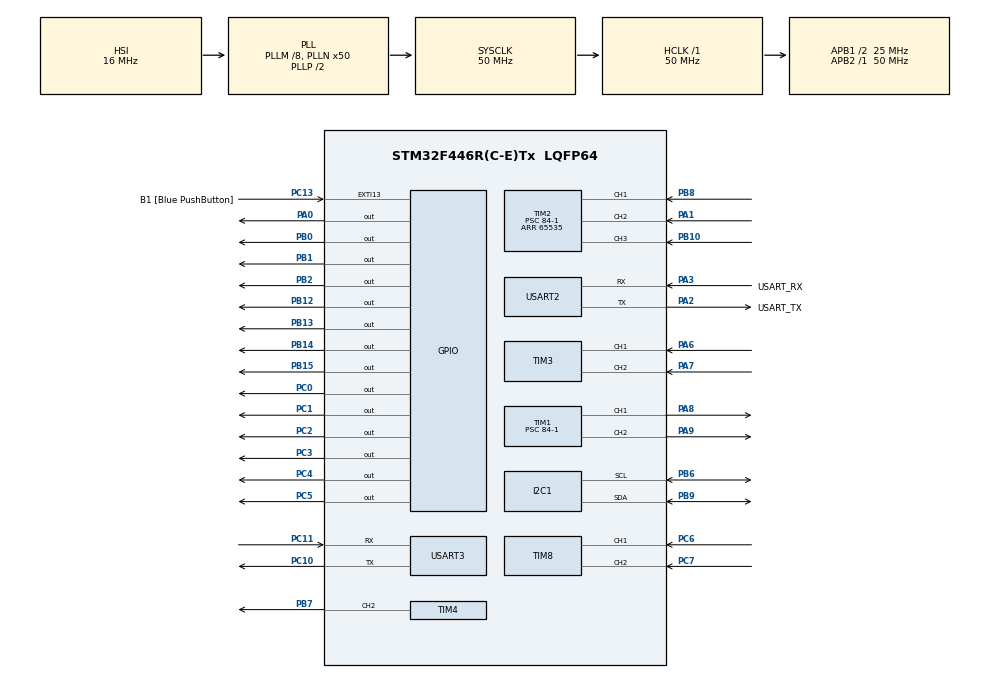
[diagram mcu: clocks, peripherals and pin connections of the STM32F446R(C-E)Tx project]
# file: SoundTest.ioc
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Dma.I2C1_RX.0.Direction=DMA_PERIPH_TO_MEMORY
Dma.I2C1_RX.0.FIFOMode=DMA_FIFOMODE_DISABLE
Dma.I2C1_RX.0.Instance=DMA1_Stream0
Dma.I2C1_RX.0.MemDataAlignment=DMA_MDATAALIGN_BYTE
Dma.I2C1_RX.0.MemInc=DMA_MINC_ENABLE
Dma.I2C1_RX.0.Mode=DMA_NORMAL
Dma.I2C1_RX.0.PeriphDataAlignment=DMA_PDATAALIGN_BYTE
Dma.I2C1_RX.0.PeriphInc=DMA_PINC_DISABLE
Dma.I2C1_RX.0.Priority=DMA_PRIORITY_HIGH
Dma.Request0=I2C1_RX
Mcu.Family=STM32F4
Mcu.Name=STM32F446R(C-E)Tx
Mcu.Package=LQFP64
NVIC.DMA1_Stream0_IRQn=true\:0\:0\:false\:false\:true\:false\:true\:true
NVIC.I2C1_ER_IRQn=true\:0\:0\:false\:false\:true\:true\:true\:true
NVIC.I2C1_EV_IRQn=true\:0\:0\:false\:false\:true\:true\:true\:true
NVIC.PriorityGroup=NVIC_PRIORITYGROUP_4
NVIC.TIM1_BRK_TIM9_IRQn=true\:0\:0\:false\:false\:true\:true\:true\:true
NVIC.TIM1_UP_TIM10_IRQn=true\:0\:0\:false\:false\:true\:true\:true\:true
NVIC.TIM2_IRQn=true\:0\:0\:false\:false\:true\:true\:true\:true
NVIC.TIM6_DAC_IRQn=true\:15\:0\:true\:false\:true\:true\:true\:true
NVIC.TIM7_IRQn=true\:0\:0\:false\:false\:true\:true\:true\:true
NVIC.USART2_IRQn=true\:0\:0\:false\:false\:true\:true\:true\:true
NVIC.USART3_IRQn=true\:0\:0\:false\:false\:true\:true\:true\:true
PA0-WKUP.Signal=GPIO_Output
PA1.Signal=S_TIM2_CH2
PA13.GPIO_Label=TMS
PA13.Mode=Serial_Wire
PA13.Signal=SYS_JTMS-SWDIO
PA14.GPIO_Label=TCK
PA14.Mode=Serial_Wire
PA14.Signal=SYS_JTCK-SWCLK
PA2.GPIO_Label=USART_TX
PA2.Mode=Asynchronous
PA2.Signal=USART2_TX
PA3.GPIO_Label=USART_RX
PA3.Mode=Asynchronous
PA3.Signal=USART2_RX
PA6.Signal=S_TIM3_CH1
PA7.Signal=S_TIM3_CH2
PA8.Signal=S_TIM1_CH1
PA9.Signal=S_TIM1_CH2
PB0.Signal=GPIO_Output
PB1.Signal=GPIO_Output
PB10.Signal=S_TIM2_CH3
PB12.Signal=GPIO_Output
PB13.Signal=GPIO_Output
PB14.Signal=GPIO_Output
PB15.Signal=GPIO_Output
PB2.Signal=GPIO_Output
PB3.GPIO_Label=SWO
PB3.Signal=SYS_JTDO-SWO
PB6.Mode=I2C
PB6.Signal=I2C1_SCL
PB7.Signal=S_TIM4_CH2
PB8.Signal=S_TIM2_CH1_ETR
PB9.Mode=I2C
PB9.Signal=I2C1_SDA
PC0.Signal=GPIO_Output
PC1.Signal=GPIO_Output
PC10.Mode=Asynchronous
PC10.Signal=USART3_TX
PC11.Mode=Asynchronous
PC11.Signal=USART3_RX
PC13.GPIO_Label=B1 [Blue PushButton]
PC13.GPIO_ModeDefaultEXTI=GPIO_MODE_IT_FALLING
PC13.Signal=GPXTI13
PC14-OSC32_IN.Mode=LSE-External-Oscillator
PC14-OSC32_IN.Signal=RCC_OSC32_IN
PC15-OSC32_OUT.Mode=LSE-External-Oscillator
PC15-OSC32_OUT.Signal=RCC_OSC32_OUT
PC2.Signal=GPIO_Output
PC3.Signal=GPIO_Output
PC4.Signal=GPIO_Output
PC5.Signal=GPIO_Output
PC6.Signal=S_TIM8_CH1
PC7.Signal=S_TIM8_CH2
PH0-OSC_IN.Mode=HSE-External-Oscillator
PH0-OSC_IN.Signal=RCC_OSC_IN
PH1-OSC_OUT.Mode=HSE-External-Oscillator
PH1-OSC_OUT.Signal=RCC_OSC_OUT
ProjectManager.HeapSize=0x200
ProjectManager.StackSize=0x400
ProjectManager.TargetToolchain=STM32CubeIDE
RCC.48MHZClocksFreq_Value=84000000
RCC.AHBFreq_Value=50000000
RCC.APB1CLKDivider=RCC_HCLK_DIV2
RCC.APB1Freq_Value=25000000
RCC.APB1TimFreq_Value=50000000
RCC.APB2Freq_Value=50000000
RCC.APB2TimFreq_Value=50000000
RCC.CortexFreq_Value=50000000
RCC.FLatency-AdvancedSettings=FLASH_LATENCY_1
RCC.HCLKFreq_Value=50000000
RCC.HSE_VALUE=8000000
RCC.HSI_VALUE=16000000
RCC.PLLM=8
RCC.PLLN=50
RCC.SYSCLKFreq_VALUE=50000000
RCC.SYSCLKSource=RCC_SYSCLKSOURCE_PLLCLK
RCC.USBFreq_Value=50000000
RCC.VCOOutputFreq_Value=100000000
SH.S_TIM1_CH1.0=TIM1_CH1,PWM Generation1 CH1
SH.S_TIM1_CH2.0=TIM1_CH2,PWM Generation2 CH2
SH.S_TIM2_CH1_ETR.0=TIM2_CH1,Input_Capture1_from_TI1
SH.S_TIM2_CH2.0=TIM2_CH2,Input_Capture2_from_TI2
SH.S_TIM2_CH3.0=TIM2_CH3,Input_Capture3_from_TI3
SH.S_TIM3_CH1.0=TIM3_CH1,Encoder_Interface
SH.S_TIM3_CH2.0=TIM3_CH2,Encoder_Interface
SH.S_TIM4_CH2.0=TIM4_CH2,PWM Generation2 CH2
SH.S_TIM8_CH1.0=TIM8_CH1,Encoder_Interface
SH.S_TIM8_CH2.0=TIM8_CH2,Encoder_Interface
TIM1.Channel-PWM\ Generation1\ CH1=TIM_CHANNEL_1
TIM1.Channel-PWM\ Generation2\ CH2=TIM_CHANNEL_2
TIM1.Period=999
TIM1.Prescaler=84-1
TIM2.Channel-Input_Capture1_from_TI1=TIM_CHANNEL_1
TIM2.Channel-Input_Capture2_from_TI2=TIM_CHANNEL_2
TIM2.Channel-Input_Capture3_from_TI3=TIM_CHANNEL_3
TIM2.Period=65535
TIM2.Prescaler=84-1
TIM4.Channel-PWM\ Generation2\ CH2=TIM_CHANNEL_2
TIM6.Period=99
TIM6.Prescaler=4999
TIM7.AutoReloadPreload=TIM_AUTORELOAD_PRELOAD_ENABLE
TIM7.Period=199
TIM7.Prescaler=4999
USART2.VirtualMode=VM_ASYNC
USART3.VirtualMode=VM_ASYNC
VP_TIM1_VS_ClockSourceINT.Mode=Internal
VP_TIM2_VS_ClockSourceINT.Mode=Internal
VP_TIM6_VS_ClockSourceINT.Mode=Enable_Timer
VP_TIM7_VS_ClockSourceINT.Mode=Enable_Timer
board=NUCLEO-F446RE

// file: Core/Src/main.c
/* USER CODE BEGIN Header */
/**
  ******************************************************************************
  * @file           : main.c
  * @brief          : Main program body
  ******************************************************************************
  * @attention
  *
  * Copyright (c) 2025 STMicroelectronics.
  * All rights reserved.
  *
  * This software is licensed under terms that can be found in the LICENSE file
  * in the root directory of this software component.
  * If no LICENSE file comes with this software, it is provided AS-IS.
  *
  ******************************************************************************
  */
/* USER CODE END Header */
#include "main.h"

/* USER CODE BEGIN Includes */
#include <stdio.h>    // printf, sprintf 사용
#include <stdarg.h>   // 가변 인자 사용
#include <math.h>
#include "ESP8266_HAL.h"
#include <string.h>   // strlen 사용
#include "stm32f4xx_hal.h" // HAL 함수 사용
#include "mpu6050.h"  // Edge-AI용 MPU6050 드라이버
#include "edge_ai_wrapper.h"  // Edge Impulse SDK Wrapper 헤더
#include "odom_imu.h"   //2D Mapping용 헤더파일

/* USER CODE END Includes */

/* USER CODE BEGIN PD */
// HC-SR04 핀 정의
#define TRIG_PIN    GPIO_PIN_0
#define TRIG_PORT    GPIOC
#define ECHO_PIN    GPIO_PIN_1
#define ECHO_PORT    GPIOA

#define TRIG_PIN1    GPIO_PIN_1
#define TRIG_PORT1    GPIOC
#define ECHO_PIN1    GPIO_PIN_8
#define ECHO_PORT1    GPIOB

#define TRIG_PIN2    GPIO_PIN_2
#define TRIG_PORT2    GPIOC
#define ECHO_PIN2    GPIO_PIN_10
#define ECHO_PORT2    GPIOB

uint8_t rx_data[100];

// 클럭 설정 (SystemClock_Config 기준 HCLK = 84MHz)
// 1초 = 84,000,000 사이클 -> 1us = 84 사이클
#define DWT_DELAY_UNIT (HAL_RCC_GetHCLKFreq() / 1000000)

// HC-SR04 관련 상수
#define SOUND_SPEED_CM_PER_US 0.0343 // 음속: 343m/s = 0.0343 cm/us
#define MAX_TIMEOUT_US 6000 // 30ms (HC-SR04 최대 측정 거리 고려)  //[최적화] 6000으로 변경

// 모터 1 (A) - ENA: TIM1_CH1 (PA8)
// 방향 핀
#define M1_IN1_PORT GPIOB
#define M1_IN1_PIN  GPIO_PIN_0
#define M1_IN2_PORT GPIOB
#define M1_IN2_PIN  GPIO_PIN_1

// 모터 2 (B) - ENB: TIM1_CH2 (PA9)
// 방향 핀
#define M2_IN1_PORT GPIOB
#define M2_IN1_PIN  GPIO_PIN_2
#define M2_IN2_PORT GPIOB
#define M2_IN2_PIN  GPIO_PIN_12

// 모터 3 (A) - ENA: TIM4_CH1 (Pb6)
#define M3_IN1_PORT GPIOC
#define M3_IN1_PIN  GPIO_PIN_3
#define M3_IN2_PORT GPIOC
#define M3_IN2_PIN  GPIO_PIN_4

// RGB LED 핀 정의
#define LED_R_PORT GPIOB
#define LED_R_PIN  GPIO_PIN_13
#define LED_G_PORT GPIOB
#define LED_G_PIN  GPIO_PIN_14
#define LED_B_PORT GPIOB
#define LED_B_PIN  GPIO_PIN_15

// RGB LED 색상 정의 (Common Cathode: Active High)
#define RGB_OFF         0, 0, 0
#define RGB_RED         1, 0, 0
#define RGB_GREEN       0, 1, 0
#define RGB_BLUE        0, 0, 1
#define RGB_YELLOW      1, 1, 0
#define RGB_MAGENTA     1, 0, 1
#define RGB_CYAN        0, 1, 1
#define RGB_WHITE       1, 1, 1

// LED 상태 타이밍 (ms)
#define LED_BLINK_INTERVAL_BASE    500   // 베이스 색상 표시 시간 (모드 색상)
#define LED_BLINK_INTERVAL_FLOOR   500   // 바닥 색상 표시 시간
#define LED_BLINK_INTERVAL_OBSTACLE 1000 // 장애물 회피 깜빡임

// LED 우선순위 상태 정의
typedef enum {
    LED_STATE_NORMAL = 0,        // 일반 동작 (모드/바닥 교차 깜빡임)
    LED_STATE_OBSTACLE = 1,      // 장애물 회피 (빨간색 깜빡임)
    LED_STATE_STANDBY = 2        // 대기 (빨간색 고정)
} LED_Priority_State_t;

// 모터 ID 및 방향 정의
#define MOTOR_A     1
#define MOTOR_B     2
#define MOTOR_C     3

#define FORWARD     1
#define BACKWARD    2
#define RIGHT    3 // 우회전
#define LEFT      4 // 좌회전 (필요시)
#define STOP        0

// PWM 최대값 (CubeMX TIM1 ARR 설정에 따라 변경될 수 있음. 여기서는 1000 가정)
#define PWM_MAX_VALUE 1000

// 벽 감지 임계 거리 (센티미터 단위)
#define WALL_DISTANCE_THRESHOLD 30.0f
// 직진 속도 및 회전 속도 (PWM 값)
#define BASE_SPEED          300
#define TURN_SPEED          300
// 회전 시간 상수 (90도 회전에 필요한 시간, 보정 필요)
#define TURN_90_TIME_MS     3200 // (모터와 바퀴에 따라 크게 달라짐)
// 유턴 시 전진/후진 거리 시간 (본체 폭만큼 이동하기 위한 시간, 보정 필요)
#define BODY_MOVE_TIME_MS   800 // 예시 값 (본체 폭에 따라 조절)

#define MPU6050_ADDR  (0x68 << 1)
#define PWR_MGMT_1    0x6B
#define ACCEL_XOUT_H  0x3B

// Edge-AI 관련 상수
#define EDGE_AI_SAMPLE_COUNT    200    // 2초 @ 100Hz (윈도우 크기)
#define EDGE_AI_AXES            3      // 3축 가속도
#define EDGE_AI_SLIDE_INTERVAL  100    // 1초마다 AI 판단 (100 샘플 = 1초)

/* USER CODE END PD */

I2C_HandleTypeDef hi2c1;
DMA_HandleTypeDef hdma_i2c1_rx;

TIM_HandleTypeDef htim1;
TIM_HandleTypeDef htim2;
TIM_HandleTypeDef htim3;
TIM_HandleTypeDef htim4;
TIM_HandleTypeDef htim6;
TIM_HandleTypeDef htim7;
TIM_HandleTypeDef htim8;

UART_HandleTypeDef huart2;
UART_HandleTypeDef huart3;

/* USER CODE BEGIN PV */
TIM_HandleTypeDef htim2;

//2D 맵핑용 위치변수
extern volatile float g_robot_x;
extern volatile float g_robot_y;
extern volatile float g_robot_yaw;

// Edge-AI 데이터 버퍼 (슬라이딩 윈도우 방식)
float edge_ai_buffer[EDGE_AI_SAMPLE_COUNT * EDGE_AI_AXES];
volatile uint16_t edge_ai_sample_index = 0;
volatile uint8_t edge_ai_buffer_ready = 0;
volatile uint16_t edge_ai_slide_counter = 0;  // 슬라이딩 인터벌 카운터

// IMU DMA 관련 변수 (비동기 I2C 통신용)
uint8_t imu_dma_buffer[6];           // DMA로 받은 6바이트 가속도 데이터
volatile uint8_t imu_dma_ready = 0;  // DMA 완료 플래그
volatile uint8_t imu_dma_busy = 0;   // DMA 전송 중 플래그

// IMU 센서 디버깅용 변수
volatile uint8_t imu_debug_counter = 0;  // 0.1초마다 출력하기 위한 카운터
volatile uint8_t imu_debug_ready = 0;    // 출력 준비 플래그
float imu_debug_ax, imu_debug_ay, imu_debug_az;  // 마지막 측정값 저장

// MQTT 관련 전역 변수
#define WIZFI360_MAX_RESPONSE_SIZE 512
char wizfi_rx_buffer[WIZFI360_MAX_RESPONSE_SIZE];

// MQTT Subscribe 수신 버퍼
#define MQTT_RX_BUF_SIZE 256
char mqtt_rx_buf[MQTT_RX_BUF_SIZE];
int mqtt_rx_len = 0;

// MQTT control 상태 변수
int g_powerOn = -1;          // 0 = OFF, 1 = ON
int g_fanSpeed = -1;         // 0~3
int g_modeManual = -1;       // 0 = AUTO, 1 = MANUAL
char g_direction[8] = "NULL";  // "FWD","BACK","LEFT","RIGHT","STOP"

// Edge-AI 판별 결과 저장 (실시간 업데이트)
char g_current_floor[16] = "Unknown";  // "Hard", "Carpet", "Dusty", "Unknown"

// LED 제어 상태 변수
LED_Priority_State_t g_led_priority_state = LED_STATE_NORMAL;
uint32_t g_led_last_update_tick = 0;
uint8_t g_led_toggle_state = 0;  // 0 or 1 (교차 깜빡임용)
/* USER CODE END PV */

void SystemClock_Config(void);
static void MX_GPIO_Init(void);
static void MX_DMA_Init(void);
static void MX_USART2_UART_Init(void);
static void MX_TIM2_Init(void);
static void MX_TIM1_Init(void);
static void MX_TIM4_Init(void);
static void MX_I2C1_Init(void);
static void MX_USART3_UART_Init(void);
static void MX_TIM3_Init(void);
static void MX_TIM8_Init(void);
static void MX_TIM6_Init(void);
static void MX_TIM7_Init(void);
/* USER CODE BEGIN PFP */
void DWT_Init(void);
void DWT_Delay_us(uint32_t us);
float HCSR04_Read(GPIO_TypeDef *trigPort, uint16_t trigPin,
                  GPIO_TypeDef *echoPort, uint16_t echoPin);
void UART_Printf(const char *format, ...);

// MQTT 함수 선언
void MQTT_ProcessResponseBuffer(uint8_t *buf, uint16_t len);

// RGB LED 제어 함수 선언
void set_rgb_led(uint8_t r, uint8_t g, uint8_t b);
void update_led_state(void);
void set_led_priority_state(LED_Priority_State_t state);

/* USER CODE END PFP */

/* USER CODE BEGIN 0 */

/**
  * @brief DWT (Data Watchpoint and Trace) 초기화 함수
  * @retval None
  */
void DWT_Init(void) {
    // TRCENA 활성화 (DWT 활성화)
    CoreDebug->DEMCR |= CoreDebug_DEMCR_TRCENA_Msk;
    // CYCCNT 카운터 초기화
    DWT->CYCCNT = 0;
    // CYCCNT 카운터 활성화
    DWT->CTRL |= DWT_CTRL_CYCCNTENA_Msk;
}

/**
  * @brief DWT 기반 마이크로초 지연 함수
  * @param us: 지연할 마이크로초
  * @retval None
  */
void DWT_Delay_us(uint32_t us) {
    uint32_t start_tick = DWT->CYCCNT;
    uint32_t delay_ticks = us * DWT_DELAY_UNIT;
    while ((DWT->CYCCNT - start_tick) < delay_ticks);
}

/**
  * @brief UART2를 이용한 printf 함수
  * @param format: 출력 형식 문자열
  * @retval None
  */
void UART_Printf(const char *format, ...) {
    char str[100];
    va_list args;
    va_start(args, format);
    vsprintf(str, format, args);
    va_end(args);
    // UART 전송 (Blocking 모드)
    HAL_UART_Transmit(&huart2, (uint8_t *)str, strlen(str), HAL_MAX_DELAY);
}

/**
  * @brief HC-SR04 거리 측정 함수
  * @retval 측정 거리 (cm), 실패 시 -1.0
  */
float HCSR04_Read(GPIO_TypeDef *trigPort, uint16_t trigPin,
                  GPIO_TypeDef *echoPort, uint16_t echoPin)
{
    uint32_t start_time, end_time, duration_cycles;

    HAL_GPIO_WritePin(trigPort, trigPin, GPIO_PIN_RESET);
    DWT_Delay_us(2);

    HAL_GPIO_WritePin(trigPort, trigPin, GPIO_PIN_SET);
    DWT_Delay_us(10);
    HAL_GPIO_WritePin(trigPort, trigPin, GPIO_PIN_RESET);

    start_time = DWT->CYCCNT;
    while (HAL_GPIO_ReadPin(echoPort, echoPin) == GPIO_PIN_RESET) {
        if ((DWT->CYCCNT - start_time) > (MAX_TIMEOUT_US * DWT_DELAY_UNIT))
            return -1.0f;
    }

    start_time = DWT->CYCCNT;
    while (HAL_GPIO_ReadPin(echoPort, echoPin) == GPIO_PIN_SET) {
        if ((DWT->CYCCNT - start_time) > (MAX_TIMEOUT_US * DWT_DELAY_UNIT))
            return -1.0f;
    }

    end_time = DWT->CYCCNT;
    duration_cycles = end_time - start_time;

    float distance = ((float)duration_cycles / (float)DWT_DELAY_UNIT)
                     * SOUND_SPEED_CM_PER_US / 2.0f;

    return distance;
}

/* 안전한 방향 제어 함수 */
void set_motor_direction(uint8_t motor_id, uint8_t direction)
{
    GPIO_TypeDef *in1_port = NULL, *in2_port = NULL;
    uint16_t in1_pin = 0, in2_pin = 0;

    if (motor_id == MOTOR_A) {
        in1_port = M1_IN1_PORT;
        in2_port = M1_IN2_PORT;
        in1_pin  = M1_IN1_PIN;
        in2_pin  = M1_IN2_PIN;
    } else if (motor_id == MOTOR_B) {
        in1_port = M2_IN1_PORT;
        in2_port = M2_IN2_PORT;
        in1_pin  = M2_IN1_PIN;
        in2_pin  = M2_IN2_PIN;
    }else if (motor_id == MOTOR_C) {
        in1_port = M3_IN1_PORT;
        in2_port = M3_IN2_PORT;
        in1_pin  = M3_IN1_PIN;
        in2_pin  = M3_IN2_PIN;
    }
    else {
        return;
    }

    if (direction == FORWARD) {
        HAL_GPIO_WritePin(in1_port, in1_pin, GPIO_PIN_SET);
        HAL_GPIO_WritePin(in2_port, in2_pin, GPIO_PIN_RESET);

    } else if (direction == BACKWARD) {
        HAL_GPIO_WritePin(in1_port, in1_pin, GPIO_PIN_RESET);
        HAL_GPIO_WritePin(in2_port, in2_pin, GPIO_PIN_SET);
    }
    else if (direction == BACKWARD) {
           HAL_GPIO_WritePin(in1_port, in1_pin, GPIO_PIN_RESET);
           HAL_GPIO_WritePin(in2_port, in2_pin, GPIO_PIN_SET);
       }
    else { // STOP (coast)
        HAL_GPIO_WritePin(in1_port, in1_pin, GPIO_PIN_RESET);
        HAL_GPIO_WritePin(in2_port, in2_pin, GPIO_PIN_RESET);
    }
}

/* 속도 설정은 그대로 사용하되 PWM_MAX와 TIM1 ARR 일치 확인 필요 */
void set_motor_speed(uint8_t motor_id, uint16_t speed)
{
    if (speed > PWM_MAX_VALUE) speed = PWM_MAX_VALUE;

    if (motor_id == MOTOR_A) {
        __HAL_TIM_SET_COMPARE(&htim1, TIM_CHANNEL_1, speed);
    } else if (motor_id == MOTOR_B) {
        __HAL_TIM_SET_COMPARE(&htim1, TIM_CHANNEL_2, speed);
    } else if (motor_id == MOTOR_C) {
        __HAL_TIM_SET_COMPARE(&htim4, TIM_CHANNEL_2, speed);
    }

}

/* --- 모터 제어 유틸 함수 추가 --- */
void stop_all_motors(void)
{
    set_motor_speed(MOTOR_A, 0);
    set_motor_speed(MOTOR_B, 0);
    set_motor_speed(MOTOR_C, 0);

    set_motor_direction(MOTOR_A, STOP);
    set_motor_direction(MOTOR_B, STOP);
    set_motor_direction(MOTOR_C, STOP);
}

void move_forward_pwm(uint16_t pwm)
{
    set_motor_direction(MOTOR_A, FORWARD);
    set_motor_direction(MOTOR_B, FORWARD);
    set_motor_speed(MOTOR_A, pwm);
    set_motor_speed(MOTOR_B, pwm);
}

void move_backward_pwm(uint16_t pwm)
{
    set_motor_direction(MOTOR_A, BACKWARD);
    set_motor_direction(MOTOR_B, BACKWARD);
    set_motor_speed(MOTOR_A, pwm);
    set_motor_speed(MOTOR_B, pwm);
}

void rotate_right_inplace(uint16_t pwm) // 오른쪽으로 제자리 회전 (좌/우 휠 반대방향)
{
    // 왼쪽 앞바퀴 전진, 오른쪽 바퀴 후진 -> 우회전
    set_motor_direction(MOTOR_A, FORWARD);   // 왼쪽
    set_motor_direction(MOTOR_B, BACKWARD);  // 오른쪽
    set_motor_speed(MOTOR_A, pwm);
    set_motor_speed(MOTOR_B, pwm);
}

void rotate_left_inplace(uint16_t pwm) // 왼쪽으로 제자리 회전
{
    set_motor_direction(MOTOR_A, BACKWARD);
    set_motor_direction(MOTOR_B, FORWARD);
    set_motor_speed(MOTOR_A, pwm);
    set_motor_speed(MOTOR_B, pwm);
}

/* 간단한 유턴: 제자리 180도 회전 (두번 90도) */
void perform_u_turn(void)
{
    // 180도: 두 번 90도 회전
    rotate_right_inplace(TURN_SPEED);
    HAL_Delay(TURN_90_TIME_MS);
    stop_all_motors();
    HAL_Delay(100);

    rotate_right_inplace(TURN_SPEED);
    HAL_Delay(TURN_90_TIME_MS);
    stop_all_motors();
    HAL_Delay(100);
}

/* 장애물 발견 시 회피 시퀀스:
   1) 정지
   2) 백업(짧게)
   3) 제자리 회전 90도 (우회전)
   4) 전진 (몸체 폭 만큼)
   5) 유턴(180)으로 라인 닫기(옵션)
*/
void R_avoidance_sequence(void)
{
    // LED 상태를 장애물 회피 모드로 설정 (빨간색 고정)
    set_led_priority_state(LED_STATE_OBSTACLE);

    // 1) 정지
    stop_all_motors();
    HAL_Delay(50);

    // 2) 백업
    move_backward_pwm(BASE_SPEED);
    HAL_Delay(300); // 300ms 뒤로 (조정 필요)
    stop_all_motors();
    HAL_Delay(50);

    // 3) 제자리 우회전 90도
    rotate_right_inplace(TURN_SPEED);
    HAL_Delay(TURN_90_TIME_MS);
    stop_all_motors();
    HAL_Delay(50);

    // 4) 전진으로 통과
    move_forward_pwm(BASE_SPEED);
    HAL_Delay(BODY_MOVE_TIME_MS);
    stop_all_motors();
    HAL_Delay(50);

    // 3) 제자리 우회전 90도
        rotate_right_inplace(TURN_SPEED);
        HAL_Delay(TURN_90_TIME_MS);
        stop_all_motors();
        HAL_Delay(50);

    // 회피 완료 후 일반 모드로 복귀
    set_led_priority_state(LED_STATE_NORMAL);
}

void L_avoidance_sequence(void)
{
    // LED 상태를 장애물 회피 모드로 설정 (빨간색 고정)
    set_led_priority_state(LED_STATE_OBSTACLE);

    // 1) 정지
    stop_all_motors();
    HAL_Delay(50);

    // 2) 백업
    move_backward_pwm(BASE_SPEED);
    HAL_Delay(300); // 300ms 뒤로 (조정 필요)
    stop_all_motors();
    HAL_Delay(50);

    // 3) 제자리 좌회전 90도
    rotate_left_inplace(TURN_SPEED);
    HAL_Delay(TURN_90_TIME_MS);
    stop_all_motors();
    HAL_Delay(50);

    // 4) 전진으로 통과
    move_forward_pwm(BASE_SPEED);
    HAL_Delay(BODY_MOVE_TIME_MS);
    stop_all_motors();
    HAL_Delay(50);

    // 3) 제자리 좌회전 90도
        rotate_left_inplace(TURN_SPEED);
        HAL_Delay(TURN_90_TIME_MS);
        stop_all_motors();
        HAL_Delay(50);

    // 회피 완료 후 일반 모드로 복귀
    set_led_priority_state(LED_STATE_NORMAL);
}

/**
  * @brief RGB LED 색상 설정 함수
  * @param r: Red 상태 (0=OFF, 1=ON)
  * @param g: Green 상태 (0=OFF, 1=ON)
  * @param b: Blue 상태 (0=OFF, 1=ON)
  * @retval None
  */
void set_rgb_led(uint8_t r, uint8_t g, uint8_t b)
{
    HAL_GPIO_WritePin(LED_R_PORT, LED_R_PIN, r ? GPIO_PIN_SET : GPIO_PIN_RESET);
    HAL_GPIO_WritePin(LED_G_PORT, LED_G_PIN, g ? GPIO_PIN_SET : GPIO_PIN_RESET);
    HAL_GPIO_WritePin(LED_B_PORT, LED_B_PIN, b ? GPIO_PIN_SET : GPIO_PIN_RESET);
}

/**
  * @brief LED 우선순위 상태 설정 함수
  * @param state: LED_STATE_NORMAL, LED_STATE_OBSTACLE, LED_STATE_STANDBY
  * @retval None
  */
void set_led_priority_state(LED_Priority_State_t state)
{
    g_led_priority_state = state;
    g_led_toggle_state = 0;  // 상태 변경 시 토글 상태 초기화
    g_led_last_update_tick = HAL_GetTick();  // 타이머 리셋
}

/**
  * @brief LED 상태 업데이트 함수 (메인 루프에서 주기적으로 호출)
  * @retval None
  * @note 우선순위: STANDBY(최고) > OBSTACLE > NORMAL
  * @note 일반 모드: 베이스 색상(1000ms) ↔ 바닥 색상(500ms) 2:1 비율
  */

void update_led_state(void)
{
    uint32_t current_tick = HAL_GetTick();
    uint32_t interval;

    // 우선순위 1: 대기 상태 (모터 정지) - 빨간색 고정
    if (g_led_priority_state == LED_STATE_STANDBY) {
        set_rgb_led(RGB_RED);
        return;
    }

    // 우선순위 2: 장애물 회피 - 빨간색 고정 (점멸 없음)
    if (g_led_priority_state == LED_STATE_OBSTACLE) {
        set_rgb_led(RGB_RED);  // 빨간색 계속 켜짐
        return;
    }

    // 우선순위 3: 일반 동작
    // Manual Mode: 파란색 고정 (점멸 없음)
    if (g_modeManual == 1) {
        set_rgb_led(RGB_BLUE);  // 수동 모드는 파란색 고정
        return;
    }

    // Auto Mode: 노면 감지에 따른 교차 깜빡임 (1:1 비율)
    // g_led_toggle_state: 0 = 하얀색(500ms), 1 = 바닥 색상(500ms)

    // 현재 표시할 색상 먼저 결정
    uint8_t base_r = 1, base_g = 1, base_b = 1;  // 하얀색

    // 바닥 색상 결정 (Edge-AI 판별 결과에 따라)
    uint8_t floor_r, floor_g, floor_b;
    if (strcmp(g_current_floor, "Hard") == 0) {
        // Hard Floor -> Green (초록색)
        floor_r = 0; floor_g = 1; floor_b = 0;
    } else if (strcmp(g_current_floor, "Carpet") == 0) {
        // Carpet -> Magenta (자홍색)
        floor_r = 1; floor_g = 0; floor_b = 1;
    } else if (strcmp(g_current_floor, "Dusty") == 0) {
        // Dusty -> Red (빨간색)
        floor_r = 1; floor_g = 0; floor_b = 0;
    } else {
        // Unknown -> Off (꺼짐)
        floor_r = 0; floor_g = 0; floor_b = 0;
    }

    // 현재 상태에 따른 interval 설정
    if (g_led_toggle_state == 0) {
        interval = LED_BLINK_INTERVAL_BASE;  // 하얀색 표시 시간 (500ms)
    } else {
        interval = LED_BLINK_INTERVAL_FLOOR; // 바닥 색상 표시 시간 (500ms)
    }

    if (current_tick - g_led_last_update_tick >= interval) {
        // 다음 색상으로 전환
        g_led_toggle_state = !g_led_toggle_state;
        g_led_last_update_tick = current_tick;
    }

    // 현재 토글 상태에 따라 LED 색상 표시
    // toggle_state = 0 → 하얀색 표시 (1000ms 유지)
    // toggle_state = 1 → 바닥 색상 표시 (500ms 유지)
    if (g_led_toggle_state == 0) {
        set_rgb_led(base_r, base_g, base_b);  // 하얀색
    } else {
        set_rgb_led(floor_r, floor_g, floor_b);  // 바닥색
    }
}

/**
  * @brief 모터 제어를 위해 필요한 초기 설정을 수행합니다.
  * @retval None
  */
void motor_control_init(void)
{
    // 1. PWM 출력 시작 (PA8: ENA, PA9: ENB)
    HAL_TIM_PWM_Start(&htim1, TIM_CHANNEL_1);
    HAL_TIM_PWM_Start(&htim1, TIM_CHANNEL_2);
    HAL_TIM_PWM_Start(&htim4, TIM_CHANNEL_2);

    // 2. 초기 모터 방향 설정 (정지)
    set_motor_direction(MOTOR_A, STOP);
    set_motor_direction(MOTOR_B, STOP);
    set_motor_direction(MOTOR_C, STOP);

    // 3. 초기 모터 속도 설정 (0)
    set_motor_speed(MOTOR_A, 0);
    set_motor_speed(MOTOR_B, 0);
    set_motor_speed(MOTOR_C, 0);

}

// 현재 control 상태를 PuTTY(USART2)에 출력하는 디버그용 함수
void Send_AT_Command(UART_HandleTypeDef *huart_wiz, UART_HandleTypeDef *huart_term, const char *command, uint8_t *response_buffer, uint16_t buffer_size, uint32_t timeout)
{
    // 1. 터미널(huart_term, PuTTY)로 전송할 명령 표시
    char tx_log[64];
    int len = snprintf(tx_log, sizeof(tx_log), "\r\n[CMD] Sending: %s\r\n", command);
    HAL_UART_Transmit(huart_term, (uint8_t *)tx_log, len, HAL_MAX_DELAY);

    // 2. WizFi360 (huart_wiz)에 명령 전송 (명령어 끝에 CR+LF(\r\n) 필수)
    char cmd_with_crlf[128];
    snprintf(cmd_with_crlf, sizeof(cmd_with_crlf), "%s\r\n", command);
    HAL_UART_Transmit(huart_wiz, (uint8_t *)cmd_with_crlf, strlen(cmd_with_crlf), 500);

    // 3. 응답 수신 준비
    memset(response_buffer, 0, buffer_size); // 버퍼 초기화
    uint16_t index = 0;
    uint32_t start_tick = HAL_GetTick();

    // 4. WizFi360으로부터 응답 수신 (간단한 타임아웃 폴링 방식)
    while ((HAL_GetTick() - start_tick) < timeout)
    {
        uint8_t rx_byte;
        // HAL_UART_Receive는 지정된 타임아웃 내에 1바이트를 수신합니다.
        if (HAL_UART_Receive(huart_wiz, &rx_byte, 1, 100) == HAL_OK)
        {
            if (index < buffer_size - 1)
            {
                response_buffer[index++] = rx_byte;
            }
            // 새로운 바이트를 수신할 때마다 타임아웃을 연장합니다.
            start_tick = HAL_GetTick();
        }
    }

    // 5. 수신된 응답을 터미널(huart_term, PuTTY)로 출력
    char *rx_header = "[RSP] Response Received:\r\n";
    HAL_UART_Transmit(huart_term, (uint8_t *)rx_header, strlen(rx_header), HAL_MAX_DELAY);

    MQTT_ProcessResponseBuffer(response_buffer, index);

    // 수신된 raw 데이터를 그대로 터미널로 출력
    HAL_UART_Transmit(huart_term, response_buffer, index, HAL_MAX_DELAY);

    char *rx_footer = "\r\n[END] ----------------------------------\r\n";
    HAL_UART_Transmit(huart_term, (uint8_t *)rx_footer, strlen(rx_footer), HAL_MAX_DELAY);
}

// 현재 control 상태를 PuTTY(USART2)에 출력하는 디버그용 함수
static void Debug_PrintControlState(const char *topic, const char *json)
{
    char buf[160];

    int len = snprintf(buf, sizeof(buf),
                       "\r\n[CONTROL] topic = %s\r\n"
                       "          json  = %s\r\n"
                       "          power = %d, speed = %d, mode = %d, dir = %s\r\n",
                       topic,
                       json,
                       g_powerOn,
                       g_fanSpeed,
                       g_modeManual,
                       g_direction);

    HAL_UART_Transmit(&huart2, (uint8_t *)buf, len, HAL_MAX_DELAY);
}

// -----------------------------------------------------
// MQTT 초기화용 공용 AT 명령 함수들
// -----------------------------------------------------

uint8_t MQTT_SetConfig(
    UART_HandleTypeDef *huart_wiz,
    UART_HandleTypeDef *huart_term,
    const char *user,
    const char *pass,
    const char *clientID,
    int aliveTime,
    uint8_t *resp, uint16_t resp_size
) {
    char cmd[256];
    snprintf(cmd, sizeof(cmd),
             "AT+MQTTSET=\"%s\",\"%s\",\"%s\",%d",
             user, pass, clientID, aliveTime);

    Send_AT_Command(huart_wiz, huart_term, cmd, resp, resp_size, 3000);
    return strstr((char*)resp, "OK") != NULL;
}

uint8_t MQTT_SetTopics(
    UART_HandleTypeDef *huart_wiz,
    UART_HandleTypeDef *huart_term,
    const char *pubTopic,
    const char *subTopic,
    uint8_t *resp, uint16_t resp_size
) {
    char cmd[256];
    snprintf(cmd, sizeof(cmd),
             "AT+MQTTTOPIC=\"%s\",\"%s\"",
             pubTopic, subTopic);

    Send_AT_Command(huart_wiz, huart_term, cmd, resp, resp_size, 3000);
    return strstr((char*)resp, "OK") != NULL;
}

uint8_t MQTT_SetQos(
    UART_HandleTypeDef *huart_wiz,
    UART_HandleTypeDef *huart_term,
    int qos,
    uint8_t *resp, uint16_t resp_size
) {
    char cmd[32];
    snprintf(cmd, sizeof(cmd), "AT+MQTTQOS=%d", qos);

    Send_AT_Command(huart_wiz, huart_term, cmd, resp, resp_size, 2000);
    return strstr((char*)resp, "OK") != NULL;
}

uint8_t MQTT_ConnectBroker(
    UART_HandleTypeDef *huart_wiz,
    UART_HandleTypeDef *huart_term,
    const char *brokerIP,
    int port,
    uint8_t *resp, uint16_t resp_size
) {
    char cmd[128];
    snprintf(cmd, sizeof(cmd),
             "AT+MQTTCON=0,\"%s\",%d",
             brokerIP, port);

    Send_AT_Command(huart_wiz, huart_term, cmd, resp, resp_size, 6000);

    return strstr((char*)resp, "CONNECT") || strstr((char*)resp, "OK");
}

uint8_t MQTT_Init_All(
    UART_HandleTypeDef *huart_wiz,
    UART_HandleTypeDef *huart_term
){
    uint8_t resp[512];

    // -------- Wi-Fi 연결 --------
    Send_AT_Command(huart_wiz, huart_term, "AT", resp, sizeof(resp), 1000);
    Send_AT_Command(huart_wiz, huart_term, "AT+RST", resp, sizeof(resp), 5000);
    Send_AT_Command(huart_wiz, huart_term, "AT+CWMODE=1", resp, sizeof(resp), 2000);

    // WiFi 접속
    Send_AT_Command(huart_wiz, huart_term,
        "AT+CWJAP=\"S24\",\"dial8787@@\"",
        resp, sizeof(resp), 5000);

    // -------- MQTT 설정 --------
    if (!MQTT_SetConfig(huart_wiz, huart_term,
                        "", "", "STM32_AI", 300,
                        resp, sizeof(resp))) return 0;

    if (!MQTT_SetTopics(huart_wiz, huart_term,
                        "vibeclean/robot1/ai2D",
                        "vibeclean/robot1/control/#",
                        resp, sizeof(resp))) return 0;

    if (!MQTT_SetQos(huart_wiz, huart_term, 0, resp, sizeof(resp)))
        return 0;

    if (!MQTT_ConnectBroker(huart_wiz, huart_term,
                            "10.96.250.61", 1883,
                            resp, sizeof(resp)))
        return 0;

    return 1;
}

void Publish_Message(void)
{
    char cmd[512];
    char json_message[400];

    // 실시간 센서 데이터와 AI 판별 결과를 포함한 JSON 생성
    snprintf(json_message, sizeof(json_message),
    		"{"
    		        "\"currentFloor\":\"%s\","
    		        "\"fanSpeed\":%d,"
    		        "\"position\":{"
    		            "\"x\":%.2f,"
    		            "\"y\":%.2f"
    		        "},"
    		        "\"sensor\":{"
    		            "\"x\":%.3f,"
    		            "\"y\":%.3f,"
    		            "\"z\":%.3f"
    		        "}"
    		    "}",
    		    g_current_floor,
    		    0,
    		    g_robot_x,
    		    g_robot_y,
    		    imu_debug_ax,
    		    imu_debug_ay,
    		    imu_debug_az
    		);

    // topic은 이미 AT+MQTTTOPIC로 설정되어 있으므로 메시지만 전달
    snprintf(cmd, sizeof(cmd), "AT+MQTTPUB=\"%s\"", json_message);
    Send_AT_Command(&huart3, &huart2, cmd, wizfi_rx_buffer, WIZFI360_MAX_RESPONSE_SIZE, 1000);
//    WizFi_SendOnly(&huart3, &huart2, cmd); //wizfi통해서 보내기만 하는 애
}

// 토픽과 JSON을 보고 상태 변수에 반영
void HandleControlJson(const char *topic, const char *json)
{
    if (strstr(topic, "control/power")) {
        if (strstr(json, "\"ON\""))  g_powerOn = 1;
        if (strstr(json, "\"OFF\"")) g_powerOn = 0;
    }
    else if (strstr(topic, "control/speed")) {
        int v = 0;
        // 숫자 하나만 뽑는 단순 파서 (예: {"fanSpeed":2})
        sscanf(json, "%*[^0-9]%d", &v);
        if (v < 0) v = 0;
        if (v > 3) v = 3;
        g_fanSpeed = v;
    }
    else if (strstr(topic, "control/mode")) {
        if (strstr(json, "\"MANUAL\"")) g_modeManual = 1;
        if (strstr(json, "\"AUTO\""))   g_modeManual = 0;
    }
    else if (strstr(topic, "control/direction")) {
        if (strstr(json, "\"FWD\""))   strcpy(g_direction, "FWD");
        else if (strstr(json, "\"BACK\""))  strcpy(g_direction, "BACK");
        else if (strstr(json, "\"LEFT\""))  strcpy(g_direction, "LEFT");
        else if (strstr(json, "\"RIGHT\"")) strcpy(g_direction, "RIGHT");
        else if (strstr(json, "\"STOP\""))  strcpy(g_direction, "STOP");
    }

    Debug_PrintControlState(topic, json);
}

// WizFi360이 보낸 한 줄(line)을 토픽 / json 으로 분리
void ParseMqttLine(char *line, int len)
{
    line[len] = '\0';

    // "topic->\"...\"" 형식에서 화살표 위치 찾기
    char *arrow = strstr(line, "->");
    if (!arrow) return;

    *arrow = '\0';
    char *topic = line;
    char *payload = arrow + 2;

    // 공백/따옴표 건너뛰기
    while (*payload == ' ' || *payload == '"' || *payload == '\r' || *payload == '\n')
        payload++;

    // JSON 시작 '{' 위치 찾기
    char *brace = strchr(payload, '{');
    if (!brace) return;

    char *end = strrchr(brace, '}');
    if (!end) return;
    *(end + 1) = '\0';   // JSON 문자열을 '\0'로 끝나게

    HandleControlJson(topic, brace);
}

// WizFi360 응답 버퍼 전체에서 "topic -> { json }" 형태의 구독 메시지를 찾아 처리
void MQTT_ProcessResponseBuffer(uint8_t *buf, uint16_t len)
{
    char line[256];
    uint16_t pos = 0;

    for (uint16_t i = 0; i < len; i++) {
        char c = (char)buf[i];

        // CR은 무시
        if (c == '\r') {
            continue;
        }

        // 줄 끝이거나 line 버퍼가 꽉 찬 경우
        if (c == '\n' || pos >= sizeof(line) - 1) {

            if (pos > 0) {
                line[pos] = '\0';

                // "->" 들어간 라인만 MQTT 메시지로 인정
                if (strstr(line, "->")) {
                    ParseMqttLine(line, strlen(line));
                }
            }

            pos = 0;
        }
        else {
            // 일반 문자는 line에 저장
            line[pos++] = c;
        }
    }

    // 마지막 라인이 '\n' 없이 종료되었을 때 처리
    if (pos > 0) {
        line[pos] = '\0';
        if (strstr(line, "->")) {
            ParseMqttLine(line, strlen(line));
        }
    }
}
/* USER CODE END 0 */

int main(void)
{

  /* USER CODE BEGIN 1 */
//Putty 작동 테스트용 변수
	int countL, countR; //  엔코더 카운트 저장 변수
	char debug_msg[100]; // 디버깅 메시지 버퍼

  /* USER CODE END 1 */

  /* MCU Configuration--------------------------------------------------------*/

  /* Reset of all peripherals, Initializes the Flash interface and the Systick. */
  HAL_Init();

  /* Configure the system clock */
  SystemClock_Config();

  /* Initialize all configured peripherals */
  MX_GPIO_Init();
  MX_DMA_Init();
  MX_USART2_UART_Init();
  MX_TIM2_Init();
  MX_TIM1_Init();
  MX_TIM4_Init();
  MX_I2C1_Init();
  MX_USART3_UART_Init();
  MX_TIM3_Init();
  MX_TIM8_Init();
  MX_TIM6_Init();
  MX_TIM7_Init();
  /* USER CODE BEGIN 2 */
  // [추가] TIM7 인터럽트 시작 (50Hz = 20ms 주기)
     if (HAL_TIM_Base_Start_IT(&htim7) != HAL_OK) {
         Error_Handler();
     }
     Odom_IMU_Init(&hi2c1, &htim3, &htim8);
     UART_Printf("Odom & IMU System Initialized (Gyro Calibrated)\r\n");

     UART_Printf("TIM7 Odometry Timer Started (50Hz)\r\n");
  // DWT 초기화 (마이크로초 측정을 위해 필수)
  DWT_Init();
  UART_Printf("STM32 HC-SR04 Measurement Ready (Trig: PA0, Echo: PA1)\r\n");

  motor_control_init(); // <- 반드시 호출 (PWM Start + 초기화)
  HAL_TIM_PWM_Start(&htim4, TIM_CHANNEL_1);

  //엔코더 카운팅 시작
  HAL_TIM_Encoder_Start(&htim3, TIM_CHANNEL_ALL);
  HAL_TIM_Encoder_Start(&htim8, TIM_CHANNEL_ALL);

  // Edge-AI 초기화
  UART_Printf("\r\n=== VibeClean ===\r\n");

  // I2C 통신 테스트
  UART_Printf("Testing I2C communication...\r\n");
  uint8_t who_am_i = MPU6050_WhoAmI(&hi2c1);
  UART_Printf("WHO_AM_I Register: 0x%02X (Expected: 0x68)\r\n", who_am_i);

  // MPU6050 센서 초기화
  UART_Printf("Initializing MPU6050...\r\n");
  HAL_StatusTypeDef mpu_status = MPU6050_Init(&hi2c1);

  if (mpu_status == HAL_OK) {
      UART_Printf("MPU6050 Init: OK\r\n");
  } else {
      UART_Printf("MPU6050 Init: FAILED! (Status: %d)\r\n", mpu_status);
      UART_Printf("Check I2C connections (SDA: PB9, SCL: PB8)\r\n");
      UART_Printf("Check MPU6050 power supply (3.3V)\r\n");
      UART_Printf("Check pull-up resistors on SDA/SCL (4.7k ohm)\r\n");
  }

  // Edge Impulse 분류기 초기화
  if (edge_ai_init() == 0) {
      UART_Printf("Edge Impulse Init: OK\r\n");
  } else {
      UART_Printf("Edge Impulse Init: FAILED!\r\n");
  }

  // TIM6 100Hz 인터럽트 시작
  HAL_TIM_Base_Start_IT(&htim6);
  UART_Printf("TIM6 100Hz Timer: Started\r\n");
  UART_Printf("Collecting %d samples (%.1f seconds)...\r\n\r\n",
              EDGE_AI_SAMPLE_COUNT, EDGE_AI_SAMPLE_COUNT / 100.0f);

  // RGB LED 초기화 (초기 상태: OFF)
  set_rgb_led(RGB_OFF);
  UART_Printf("RGB LED: Initialized\r\n");

  /* USER CODE END 2 */

  /* Infinite loop */
  /* USER CODE BEGIN WHILE */
  int failCount = 0;
  int tempAovoid = 0; // 0 = right, 1 = left

  char post_data_buffer[150]; //json 문자열 버퍼
  uint32_t last_pub_tick = 0; // 마지막 메시지 발행 시간 저장

  char *start_msg = "STM32 WizFi360 MQTT Test Start! (PuTTY=USART2, WizFi360=USART3)\r\n";
  //  HAL_UART_Transmit(&huart2, (uint8_t *)start_msg, strlen(start_msg), HAL_MAX_DELAY);

  HAL_Delay(3000); // WizFi360 부팅 대기

  //  Setup_WiFi_And_MQTT();
  MQTT_Init_All(&huart3, &huart2);   // Wiz: huart1, Terminal: huart2

  while (1)
  {
	  // ==========================================================
	  // [1] MQTT Publish & Data Receiving (데이터 수신/발신 통합)
	  // ==========================================================
	  // Publish 함수 내부에서 AT 커맨드 응답을 기다릴 때
	  // Subscribe 수동조작 명령도 같이 수신하여 처리함.
	        uint32_t now_tick = HAL_GetTick();
	        if (now_tick - last_pub_tick >= 600) { // 1000 = 1초 주기 (필요시 단축 가능)
	            Publish_Message();
	            last_pub_tick = now_tick;
	        }

	  // ==========================================================
	  // [2] POWER OFF 체크 (조건 1)
	  // ==========================================================
	  // OFF 상태면 모터 정지 후 다음 루프로 넘어감 (주행 로직 Skip)
	        if (g_powerOn == 0) {
	            stop_all_motors();
	            set_led_priority_state(LED_STATE_STANDBY);  // 대기 상태 LED (빨간색 고정)
	            // set_motor_speed(MOTOR_C, 0); // 팬도 끄기 (필요시)
	            HAL_Delay(100);
	            continue;
	        }

	  // ==========================================================
	  // [3] FAN SPEED 제어 (Fan 연결후 수정필요)
	  // ==========================================================
//	        if (g_fanSpeed != -1) {
//	            // 수동 값(0~3)이 있으면 강제 적용
//	            int pwm_val = 0;
//	            if (g_fanSpeed == 1) pwm_val = 300;
//	            else if (g_fanSpeed == 2) pwm_val = 600;
//	            else if (g_fanSpeed == 3) pwm_val = 1000;
//
//	            set_motor_speed(MOTOR_C, pwm_val);
//	        } else {
//	            // -1이면 노면 상태(g_current_floor)에 따라 자동 제어 (추후 구현)
//	        }

	  // ==========================================================
	  // [4] 센서 및 AI 업데이트
	  // ==========================================================
      // === RGB LED 상태 업데이트 (논블로킹 방식) ===
      update_led_state();

      // === IMU 센서 디버깅 출력 (0.1초마다) ===
      if (imu_debug_ready) {
          UART_Printf("[IMU] Ax: %.3fg, Ay: %.3fg, Az: %.3fg\r\n",
                     imu_debug_ax, imu_debug_ay, imu_debug_az);
          imu_debug_ready = 0;  // 플래그 리셋
      }

      // === Edge-AI 테스트 코드 ===
      if (edge_ai_buffer_ready) {
          surface_classification_t result = {0};

          // Edge Impulse 분류기 실행
          if (edge_ai_classify(edge_ai_buffer, EDGE_AI_SAMPLE_COUNT * EDGE_AI_AXES, &result) == 0) {
              // 판별 결과 출력 (Hard, Carpet, Dusty - 대문자 시작)
              UART_Printf("[AI] Hard: %.2f, Carpet: %.2f, Dusty: %.2f\r\n",
                         result.Hard, result.Carpet, result.Dusty);

              // 가장 높은 확률의 노면 타입 저장
              if (result.Hard >= result.Carpet && result.Hard >= result.Dusty) {
                  strcpy(g_current_floor, "Hard");
              } else if (result.Carpet >= result.Hard && result.Carpet >= result.Dusty) {
                  strcpy(g_current_floor, "Carpet");
              } else {
                  strcpy(g_current_floor, "Dusty");
              }
          } else {
              UART_Printf("[AI] Classification FAILED\r\n");
              strcpy(g_current_floor, "Unknown");
          }

          // 버퍼 준비 완료 플래그 리셋
          edge_ai_buffer_ready = 0;
      }

       // ==========================================================
       // [5] 주행 모드 분기
       // ==========================================================

       // g_modeManual이 1이면 수동, 그 외(0 또는 -1)는 자동
            if (g_modeManual == 1)
            {
                // ------------------------------------------------------
                // < MANUAL MODE > 장애물 감지 무시, 사용자 명령 수행
                // ------------------------------------------------------
                if (strcmp(g_direction, "FWD") == 0) {
                    move_forward_pwm(BASE_SPEED);
                }
                else if (strcmp(g_direction, "BACK") == 0) {
                    move_backward_pwm(BASE_SPEED);
                }
                else if (strcmp(g_direction, "LEFT") == 0) {
                    rotate_left_inplace(TURN_SPEED);
                }
                else if (strcmp(g_direction, "RIGHT") == 0) {
                    rotate_right_inplace(TURN_SPEED);
                }
                else {
                    // "STOP" 이거나 "NULL" 이면 정지
                    stop_all_motors();
                }
            }
            else
             {
      // === 자동 모드: 장애물 회피 및 노면 감지 기반 주행 ===
      set_led_priority_state(LED_STATE_NORMAL);  // 일반 동작 LED 상태로 설정

      // 전진 유지
      move_forward_pwm(BASE_SPEED);

      // 초음파 센서로 거리 측정
      float d1 = HCSR04_Read(TRIG_PORT, TRIG_PIN, ECHO_PORT, ECHO_PIN);
      DWT_Delay_us(5000);
      float d2 = HCSR04_Read(TRIG_PORT1, TRIG_PIN1, ECHO_PORT1, ECHO_PIN1);
      DWT_Delay_us(5000);
      float d3 = HCSR04_Read(TRIG_PORT2, TRIG_PIN2, ECHO_PORT2, ECHO_PIN2);

      // UART_Printf("[USS] S1: %.1fcm | S2: %.1fcm | S3: %.1fcm\r\n", d1, d2, d3);

      // 장애물 감지 및 회피
      if ((d1 > 1 && d1 <= WALL_DISTANCE_THRESHOLD)
                || (d2 > 1 && d2 <= WALL_DISTANCE_THRESHOLD)
                || (d3 > 1 && d3 <= WALL_DISTANCE_THRESHOLD)) {
          failCount++;
          if (failCount >= 3) { // 연속 3회 이상이면 진짜 장애물
              stop_all_motors();
              HAL_Delay(50);

              UART_Printf("[AVOID] Obstacle detected! Avoiding...\r\n");

              if(tempAovoid == 0){
                 R_avoidance_sequence();
                 tempAovoid = 1;
              }
              else{
                 L_avoidance_sequence();
                 tempAovoid = 0;
              }
              failCount = 0;
          }
      } else {
          failCount = 0;
      }

             }

            HAL_Delay(1);
//      // === MQTT 메시지 발행 (5초마다) ===    //위치이동하고 주석 처리하였습니다.
//      uint32_t now_tick = HAL_GetTick();
//      if (now_tick - last_pub_tick >= 1000) {
//          Publish_Message();
//          last_pub_tick = now_tick;
//      }

//     MPU6050_Read_Accel(&Ax, &Ay, &Az);
//
//         // g 단위 변환
//         float ax_g = Ax / 16384.0f;
//         float ay_g = Ay / 16384.0f;
//         float az_g = Az / 16384.0f;
//
//         // Roll / Pitch 계산
//         float roll  = atan2f(ay_g, az_g) * 180.0f / 3.14159265f;
//         float pitch = atan2f(-ax_g, sqrtf(ay_g*ay_g + az_g*az_g)) * 180.0f / 3.14159265f;
//
//         // UART로 출력
//         char buf[100];
//         sprintf(buf, "Roll: %.2f  Pitch: %.2f\r\n", roll, pitch);
//         HAL_UART_Transmit(&huart2, (uint8_t*)buf, strlen(buf), 1000);
//
//         HAL_Delay(500);
//      //전진 유지
//     move_forward_pwm(BASE_SPEED);
//
//         d1 = HCSR04_Read(TRIG_PORT, TRIG_PIN, ECHO_PORT, ECHO_PIN);
//         DWT_Delay_us(5000);
//         d2 = HCSR04_Read(TRIG_PORT1, TRIG_PIN1, ECHO_PORT1, ECHO_PIN1);
//         DWT_Delay_us(5000);
//         d3 = HCSR04_Read(TRIG_PORT2, TRIG_PIN2, ECHO_PORT2, ECHO_PIN2);
//
//         UART_Printf("S1: %.1f cm | S2: %.1f cm | S3: %.1f cm\r\n", d1, d2, d3);
//
//         // 센서값 모두 0이면 일시적인 에러로 간주
//         if ((d1 > 1 && d1 <= WALL_DISTANCE_THRESHOLD)
//                   || (d2 > 1 && d2 <= WALL_DISTANCE_THRESHOLD)
//                   || (d3 > 1 && d3 <= WALL_DISTANCE_THRESHOLD)) {
//             failCount++;
//             if (failCount > 5) { // 연속 3회 이상이면 진짜 장애물일 수도 있음
//                 stop_all_motors();
//                 HAL_Delay(50);
//                 if(tempAovoid == 0){
//                    R_avoidance_sequence();
//                    tempAovoid = 1;
//                 }
//                 else{
//                    L_avoidance_sequence();
//                    tempAovoid = 0;
//
//                 }
//                 failCount = 0;
//             }
//         } else {
//             failCount = 0;
//         }
//
//
//         HAL_Delay(100);
//
//

     /* USER CODE BEGIN WHILE */

//
//      센서 1에서 거리 읽기
//         distance1 = HCSR04_Read(TRIG_PORT, TRIG_PIN, ECHO_PORT, ECHO_PIN);
//
//         // 센서 2에서 거리 읽기
//         distance2 = HCSR04_Read(TRIG_PORT1, TRIG_PIN1, ECHO_PORT1, ECHO_PIN1);
//
//         // 센서 2에서 거리 읽기
//         distance3 = HCSR04_Read(TRIG_PORT2, TRIG_PIN2, ECHO_PORT2, ECHO_PIN2);
//
//         // 결과 출력
//         if (distance1 > 0)
//             UART_Printf("S1: %.2f cm  ", distance1);
//         else
//             UART_Printf("S1: Fail  ");
//
//         if (distance2 > 0)
//             UART_Printf("S2: %.2f cm  ", distance2);
//         else
//             UART_Printf("S2: Fail\r\n");
//
//         if (distance3 > 0)
//                      UART_Printf("S3: %.2f cm\r\n", distance3);
//                  else
//                      UART_Printf("S3: Fail\r\n");
//
//         HAL_Delay(500);
    /* USER CODE END WHILE */

  }
}

void SystemClock_Config(void)
{
  RCC_OscInitTypeDef RCC_OscInitStruct = {0};
  RCC_ClkInitTypeDef RCC_ClkInitStruct = {0};

  /** Configure the main internal regulator output voltage
  */
  __HAL_RCC_PWR_CLK_ENABLE();
  __HAL_PWR_VOLTAGESCALING_CONFIG(PWR_REGULATOR_VOLTAGE_SCALE3);

  /** Initializes the RCC Oscillators according to the specified parameters
  * in the RCC_OscInitTypeDef structure.
  */
  RCC_OscInitStruct.OscillatorType = RCC_OSCILLATORTYPE_HSI;
  RCC_OscInitStruct.HSIState = RCC_HSI_ON;
  RCC_OscInitStruct.HSICalibrationValue = RCC_HSICALIBRATION_DEFAULT;
  RCC_OscInitStruct.PLL.PLLState = RCC_PLL_ON;
  RCC_OscInitStruct.PLL.PLLSource = RCC_PLLSOURCE_HSI;
  RCC_OscInitStruct.PLL.PLLM = 8;
  RCC_OscInitStruct.PLL.PLLN = 50;
  RCC_OscInitStruct.PLL.PLLP = RCC_PLLP_DIV2;
  RCC_OscInitStruct.PLL.PLLQ = 2;
  RCC_OscInitStruct.PLL.PLLR = 2;
  if (HAL_RCC_OscConfig(&RCC_OscInitStruct) != HAL_OK)
  {
    Error_Handler();
  }

  /** Initializes the CPU, AHB and APB buses clocks
  */
  RCC_ClkInitStruct.ClockType = RCC_CLOCKTYPE_HCLK|RCC_CLOCKTYPE_SYSCLK
                              |RCC_CLOCKTYPE_PCLK1|RCC_CLOCKTYPE_PCLK2;
  RCC_ClkInitStruct.SYSCLKSource = RCC_SYSCLKSOURCE_PLLCLK;
  RCC_ClkInitStruct.AHBCLKDivider = RCC_SYSCLK_DIV1;
  RCC_ClkInitStruct.APB1CLKDivider = RCC_HCLK_DIV2;
  RCC_ClkInitStruct.APB2CLKDivider = RCC_HCLK_DIV1;

  if (HAL_RCC_ClockConfig(&RCC_ClkInitStruct, FLASH_LATENCY_1) != HAL_OK)
  {
    Error_Handler();
  }
}

static void MX_I2C1_Init(void)
{

  hi2c1.Instance = I2C1;
  hi2c1.Init.ClockSpeed = 100000;
  hi2c1.Init.DutyCycle = I2C_DUTYCYCLE_2;
  hi2c1.Init.OwnAddress1 = 0;
  hi2c1.Init.AddressingMode = I2C_ADDRESSINGMODE_7BIT;
  hi2c1.Init.DualAddressMode = I2C_DUALADDRESS_DISABLE;
  hi2c1.Init.OwnAddress2 = 0;
  hi2c1.Init.GeneralCallMode = I2C_GENERALCALL_DISABLE;
  hi2c1.Init.NoStretchMode = I2C_NOSTRETCH_DISABLE;
  if (HAL_I2C_Init(&hi2c1) != HAL_OK)
  {
    Error_Handler();
  }

}

static void MX_TIM1_Init(void)
{

  TIM_ClockConfigTypeDef sClockSourceConfig = {0};
  TIM_MasterConfigTypeDef sMasterConfig = {0};
  TIM_OC_InitTypeDef sConfigOC = {0};
  TIM_BreakDeadTimeConfigTypeDef sBreakDeadTimeConfig = {0};

  htim1.Instance = TIM1;
  htim1.Init.Prescaler = 84-1;
  htim1.Init.CounterMode = TIM_COUNTERMODE_UP;
  htim1.Init.Period = 999;
  htim1.Init.ClockDivision = TIM_CLOCKDIVISION_DIV1;
  htim1.Init.RepetitionCounter = 0;
  htim1.Init.AutoReloadPreload = TIM_AUTORELOAD_PRELOAD_DISABLE;
  if (HAL_TIM_Base_Init(&htim1) != HAL_OK)
  {
    Error_Handler();
  }
  sClockSourceConfig.ClockSource = TIM_CLOCKSOURCE_INTERNAL;
  if (HAL_TIM_ConfigClockSource(&htim1, &sClockSourceConfig) != HAL_OK)
  {
    Error_Handler();
  }
  if (HAL_TIM_PWM_Init(&htim1) != HAL_OK)
  {
    Error_Handler();
  }
  sMasterConfig.MasterOutputTrigger = TIM_TRGO_RESET;
  sMasterConfig.MasterSlaveMode = TIM_MASTERSLAVEMODE_DISABLE;
  if (HAL_TIMEx_MasterConfigSynchronization(&htim1, &sMasterConfig) != HAL_OK)
  {
    Error_Handler();
  }
  sConfigOC.OCMode = TIM_OCMODE_PWM1;
  sConfigOC.Pulse = 0;
  sConfigOC.OCPolarity = TIM_OCPOLARITY_HIGH;
  sConfigOC.OCNPolarity = TIM_OCNPOLARITY_HIGH;
  sConfigOC.OCFastMode = TIM_OCFAST_DISABLE;
  sConfigOC.OCIdleState = TIM_OCIDLESTATE_RESET;
  sConfigOC.OCNIdleState = TIM_OCNIDLESTATE_RESET;
  if (HAL_TIM_PWM_ConfigChannel(&htim1, &sConfigOC, TIM_CHANNEL_1) != HAL_OK)
  {
    Error_Handler();
  }
  if (HAL_TIM_PWM_ConfigChannel(&htim1, &sConfigOC, TIM_CHANNEL_2) != HAL_OK)
  {
    Error_Handler();
  }
  sBreakDeadTimeConfig.OffStateRunMode = TIM_OSSR_DISABLE;
  sBreakDeadTimeConfig.OffStateIDLEMode = TIM_OSSI_DISABLE;
  sBreakDeadTimeConfig.LockLevel = TIM_LOCKLEVEL_OFF;
  sBreakDeadTimeConfig.DeadTime = 0;
  sBreakDeadTimeConfig.BreakState = TIM_BREAK_DISABLE;
  sBreakDeadTimeConfig.BreakPolarity = TIM_BREAKPOLARITY_HIGH;
  sBreakDeadTimeConfig.AutomaticOutput = TIM_AUTOMATICOUTPUT_DISABLE;
  if (HAL_TIMEx_ConfigBreakDeadTime(&htim1, &sBreakDeadTimeConfig) != HAL_OK)
  {
    Error_Handler();
  }
  HAL_TIM_MspPostInit(&htim1);

}

static void MX_TIM2_Init(void)
{

  TIM_ClockConfigTypeDef sClockSourceConfig = {0};
  TIM_MasterConfigTypeDef sMasterConfig = {0};
  TIM_IC_InitTypeDef sConfigIC = {0};

  htim2.Instance = TIM2;
  htim2.Init.Prescaler = 84-1;
  htim2.Init.CounterMode = TIM_COUNTERMODE_UP;
  htim2.Init.Period = 65535;
  htim2.Init.ClockDivision = TIM_CLOCKDIVISION_DIV1;
  htim2.Init.AutoReloadPreload = TIM_AUTORELOAD_PRELOAD_DISABLE;
  if (HAL_TIM_Base_Init(&htim2) != HAL_OK)
  {
    Error_Handler();
  }
  sClockSourceConfig.ClockSource = TIM_CLOCKSOURCE_INTERNAL;
  if (HAL_TIM_ConfigClockSource(&htim2, &sClockSourceConfig) != HAL_OK)
  {
    Error_Handler();
  }
  if (HAL_TIM_IC_Init(&htim2) != HAL_OK)
  {
    Error_Handler();
  }
  sMasterConfig.MasterOutputTrigger = TIM_TRGO_RESET;
  sMasterConfig.MasterSlaveMode = TIM_MASTERSLAVEMODE_DISABLE;
  if (HAL_TIMEx_MasterConfigSynchronization(&htim2, &sMasterConfig) != HAL_OK)
  {
    Error_Handler();
  }
  sConfigIC.ICPolarity = TIM_INPUTCHANNELPOLARITY_RISING;
  sConfigIC.ICSelection = TIM_ICSELECTION_DIRECTTI;
  sConfigIC.ICPrescaler = TIM_ICPSC_DIV1;
  sConfigIC.ICFilter = 0;
  if (HAL_TIM_IC_ConfigChannel(&htim2, &sConfigIC, TIM_CHANNEL_1) != HAL_OK)
  {
    Error_Handler();
  }
  if (HAL_TIM_IC_ConfigChannel(&htim2, &sConfigIC, TIM_CHANNEL_2) != HAL_OK)
  {
    Error_Handler();
  }
  if (HAL_TIM_IC_ConfigChannel(&htim2, &sConfigIC, TIM_CHANNEL_3) != HAL_OK)
  {
    Error_Handler();
  }

}

static void MX_TIM3_Init(void)
{

  TIM_Encoder_InitTypeDef sConfig = {0};
  TIM_MasterConfigTypeDef sMasterConfig = {0};

  htim3.Instance = TIM3;
  htim3.Init.Prescaler = 0;
  htim3.Init.CounterMode = TIM_COUNTERMODE_UP;
  htim3.Init.Period = 65535;
  htim3.Init.ClockDivision = TIM_CLOCKDIVISION_DIV1;
  htim3.Init.AutoReloadPreload = TIM_AUTORELOAD_PRELOAD_DISABLE;
  sConfig.EncoderMode = TIM_ENCODERMODE_TI1;
  sConfig.IC1Polarity = TIM_ICPOLARITY_RISING;
  sConfig.IC1Selection = TIM_ICSELECTION_DIRECTTI;
  sConfig.IC1Prescaler = TIM_ICPSC_DIV1;
  sConfig.IC1Filter = 0;
  sConfig.IC2Polarity = TIM_ICPOLARITY_RISING;
  sConfig.IC2Selection = TIM_ICSELECTION_DIRECTTI;
  sConfig.IC2Prescaler = TIM_ICPSC_DIV1;
  sConfig.IC2Filter = 0;
  if (HAL_TIM_Encoder_Init(&htim3, &sConfig) != HAL_OK)
  {
    Error_Handler();
  }
  sMasterConfig.MasterOutputTrigger = TIM_TRGO_RESET;
  sMasterConfig.MasterSlaveMode = TIM_MASTERSLAVEMODE_DISABLE;
  if (HAL_TIMEx_MasterConfigSynchronization(&htim3, &sMasterConfig) != HAL_OK)
  {
    Error_Handler();
  }

}

static void MX_TIM4_Init(void)
{

  TIM_MasterConfigTypeDef sMasterConfig = {0};
  TIM_OC_InitTypeDef sConfigOC = {0};

  htim4.Instance = TIM4;
  htim4.Init.Prescaler = 0;
  htim4.Init.CounterMode = TIM_COUNTERMODE_UP;
  htim4.Init.Period = 65535;
  htim4.Init.ClockDivision = TIM_CLOCKDIVISION_DIV1;
  htim4.Init.AutoReloadPreload = TIM_AUTORELOAD_PRELOAD_DISABLE;
  if (HAL_TIM_PWM_Init(&htim4) != HAL_OK)
  {
    Error_Handler();
  }
  sMasterConfig.MasterOutputTrigger = TIM_TRGO_RESET;
  sMasterConfig.MasterSlaveMode = TIM_MASTERSLAVEMODE_DISABLE;
  if (HAL_TIMEx_MasterConfigSynchronization(&htim4, &sMasterConfig) != HAL_OK)
  {
    Error_Handler();
  }
  sConfigOC.OCMode = TIM_OCMODE_PWM1;
  sConfigOC.Pulse = 0;
  sConfigOC.OCPolarity = TIM_OCPOLARITY_HIGH;
  sConfigOC.OCFastMode = TIM_OCFAST_DISABLE;
  if (HAL_TIM_PWM_ConfigChannel(&htim4, &sConfigOC, TIM_CHANNEL_2) != HAL_OK)
  {
    Error_Handler();
  }
  HAL_TIM_MspPostInit(&htim4);

}

static void MX_TIM6_Init(void)
{

  TIM_MasterConfigTypeDef sMasterConfig = {0};

  htim6.Instance = TIM6;
  htim6.Init.Prescaler = 4999;
  htim6.Init.CounterMode = TIM_COUNTERMODE_UP;
  htim6.Init.Period = 99;
  htim6.Init.AutoReloadPreload = TIM_AUTORELOAD_PRELOAD_DISABLE;
  if (HAL_TIM_Base_Init(&htim6) != HAL_OK)
  {
    Error_Handler();
  }
  sMasterConfig.MasterOutputTrigger = TIM_TRGO_RESET;
  sMasterConfig.MasterSlaveMode = TIM_MASTERSLAVEMODE_DISABLE;
  if (HAL_TIMEx_MasterConfigSynchronization(&htim6, &sMasterConfig) != HAL_OK)
  {
    Error_Handler();
  }

}

static void MX_TIM7_Init(void)
{

  TIM_MasterConfigTypeDef sMasterConfig = {0};

  htim7.Instance = TIM7;
  htim7.Init.Prescaler = 4999;
  htim7.Init.CounterMode = TIM_COUNTERMODE_UP;
  htim7.Init.Period = 199;
  htim7.Init.AutoReloadPreload = TIM_AUTORELOAD_PRELOAD_ENABLE;
  if (HAL_TIM_Base_Init(&htim7) != HAL_OK)
  {
    Error_Handler();
  }
  sMasterConfig.MasterOutputTrigger = TIM_TRGO_RESET;
  sMasterConfig.MasterSlaveMode = TIM_MASTERSLAVEMODE_DISABLE;
  if (HAL_TIMEx_MasterConfigSynchronization(&htim7, &sMasterConfig) != HAL_OK)
  {
    Error_Handler();
  }

}

static void MX_TIM8_Init(void)
{

  TIM_Encoder_InitTypeDef sConfig = {0};
  TIM_MasterConfigTypeDef sMasterConfig = {0};

  htim8.Instance = TIM8;
  htim8.Init.Prescaler = 0;
  htim8.Init.CounterMode = TIM_COUNTERMODE_UP;
  htim8.Init.Period = 65535;
  htim8.Init.ClockDivision = TIM_CLOCKDIVISION_DIV1;
  htim8.Init.RepetitionCounter = 0;
  htim8.Init.AutoReloadPreload = TIM_AUTORELOAD_PRELOAD_DISABLE;
  sConfig.EncoderMode = TIM_ENCODERMODE_TI1;
  sConfig.IC1Polarity = TIM_ICPOLARITY_RISING;
  sConfig.IC1Selection = TIM_ICSELECTION_DIRECTTI;
  sConfig.IC1Prescaler = TIM_ICPSC_DIV1;
  sConfig.IC1Filter = 0;
  sConfig.IC2Polarity = TIM_ICPOLARITY_RISING;
  sConfig.IC2Selection = TIM_ICSELECTION_DIRECTTI;
  sConfig.IC2Prescaler = TIM_ICPSC_DIV1;
  sConfig.IC2Filter = 0;
  if (HAL_TIM_Encoder_Init(&htim8, &sConfig) != HAL_OK)
  {
    Error_Handler();
  }
  sMasterConfig.MasterOutputTrigger = TIM_TRGO_RESET;
  sMasterConfig.MasterSlaveMode = TIM_MASTERSLAVEMODE_DISABLE;
  if (HAL_TIMEx_MasterConfigSynchronization(&htim8, &sMasterConfig) != HAL_OK)
  {
    Error_Handler();
  }

}

static void MX_USART2_UART_Init(void)
{

  huart2.Instance = USART2;
  huart2.Init.BaudRate = 115200;
  huart2.Init.WordLength = UART_WORDLENGTH_8B;
  huart2.Init.StopBits = UART_STOPBITS_1;
  huart2.Init.Parity = UART_PARITY_NONE;
  huart2.Init.Mode = UART_MODE_TX_RX;
  huart2.Init.HwFlowCtl = UART_HWCONTROL_NONE;
  huart2.Init.OverSampling = UART_OVERSAMPLING_16;
  if (HAL_UART_Init(&huart2) != HAL_OK)
  {
    Error_Handler();
  }

}

static void MX_USART3_UART_Init(void)
{

  huart3.Instance = USART3;
  huart3.Init.BaudRate = 115200;
  huart3.Init.WordLength = UART_WORDLENGTH_8B;
  huart3.Init.StopBits = UART_STOPBITS_1;
  huart3.Init.Parity = UART_PARITY_NONE;
  huart3.Init.Mode = UART_MODE_TX_RX;
  huart3.Init.HwFlowCtl = UART_HWCONTROL_NONE;
  huart3.Init.OverSampling = UART_OVERSAMPLING_16;
  if (HAL_UART_Init(&huart3) != HAL_OK)
  {
    Error_Handler();
  }

}

static void MX_DMA_Init(void)
{

  /* DMA controller clock enable */
  __HAL_RCC_DMA1_CLK_ENABLE();

  /* DMA interrupt init */
  /* DMA1_Stream0_IRQn interrupt configuration */
  HAL_NVIC_SetPriority(DMA1_Stream0_IRQn, 0, 0);
  HAL_NVIC_EnableIRQ(DMA1_Stream0_IRQn);

}

static void MX_GPIO_Init(void)
{
  GPIO_InitTypeDef GPIO_InitStruct = {0};

  /* GPIO Ports Clock Enable */
  __HAL_RCC_GPIOC_CLK_ENABLE();
  __HAL_RCC_GPIOH_CLK_ENABLE();
  __HAL_RCC_GPIOA_CLK_ENABLE();
  __HAL_RCC_GPIOB_CLK_ENABLE();

  /*Configure GPIO pin Output Level */
  HAL_GPIO_WritePin(GPIOC, GPIO_PIN_0|GPIO_PIN_1|GPIO_PIN_2|GPIO_PIN_3
                          |GPIO_PIN_4|GPIO_PIN_5, GPIO_PIN_RESET);

  /*Configure GPIO pin Output Level */
  HAL_GPIO_WritePin(GPIOA, GPIO_PIN_0, GPIO_PIN_RESET);

  /*Configure GPIO pin Output Level */
  HAL_GPIO_WritePin(GPIOB, GPIO_PIN_0|GPIO_PIN_1|GPIO_PIN_2|GPIO_PIN_12
                          |GPIO_PIN_13|GPIO_PIN_14|GPIO_PIN_15, GPIO_PIN_RESET);

  /*Configure GPIO pin : B1_Pin */
  GPIO_InitStruct.Pin = B1_Pin;
  GPIO_InitStruct.Mode = GPIO_MODE_IT_FALLING;
  GPIO_InitStruct.Pull = GPIO_NOPULL;
  HAL_GPIO_Init(B1_GPIO_Port, &GPIO_InitStruct);

  /*Configure GPIO pins : PC0 PC1 PC2 PC3
                           PC4 PC5 */
  GPIO_InitStruct.Pin = GPIO_PIN_0|GPIO_PIN_1|GPIO_PIN_2|GPIO_PIN_3
                          |GPIO_PIN_4|GPIO_PIN_5;
  GPIO_InitStruct.Mode = GPIO_MODE_OUTPUT_PP;
  GPIO_InitStruct.Pull = GPIO_NOPULL;
  GPIO_InitStruct.Speed = GPIO_SPEED_FREQ_LOW;
  HAL_GPIO_Init(GPIOC, &GPIO_InitStruct);

  /*Configure GPIO pin : PA0 */
  GPIO_InitStruct.Pin = GPIO_PIN_0;
  GPIO_InitStruct.Mode = GPIO_MODE_OUTPUT_PP;
  GPIO_InitStruct.Pull = GPIO_NOPULL;
  GPIO_InitStruct.Speed = GPIO_SPEED_FREQ_LOW;
  HAL_GPIO_Init(GPIOA, &GPIO_InitStruct);

  /*Configure GPIO pins : PB0 PB1 PB2 PB12
                           PB13 PB14 PB15 */
  GPIO_InitStruct.Pin = GPIO_PIN_0|GPIO_PIN_1|GPIO_PIN_2|GPIO_PIN_12
                          |GPIO_PIN_13|GPIO_PIN_14|GPIO_PIN_15;
  GPIO_InitStruct.Mode = GPIO_MODE_OUTPUT_PP;
  GPIO_InitStruct.Pull = GPIO_NOPULL;
  GPIO_InitStruct.Speed = GPIO_SPEED_FREQ_LOW;
  HAL_GPIO_Init(GPIOB, &GPIO_InitStruct);

  /* USER CODE BEGIN MX_GPIO_Init_2 */
  // PA0 (Trig) Output 설정
  GPIO_InitStruct.Pin = TRIG_PIN; // PA0
  GPIO_InitStruct.Mode = GPIO_MODE_OUTPUT_PP;
  GPIO_InitStruct.Pull = GPIO_NOPULL;
  GPIO_InitStruct.Speed = GPIO_SPEED_FREQ_HIGH;
  HAL_GPIO_Init(TRIG_PORT, &GPIO_InitStruct);

  // PA1 (Echo) Input 설정
  GPIO_InitStruct.Pin = ECHO_PIN; // PA1
  GPIO_InitStruct.Mode = GPIO_MODE_INPUT;
  GPIO_InitStruct.Pull = GPIO_NOPULL; // HC-SR04는 보통 풀업/풀다운 불필요
  HAL_GPIO_Init(ECHO_PORT, &GPIO_InitStruct);

  // S2: PC1 (TRIG), PA15 (ECHO)
  GPIO_InitStruct.Pin = TRIG_PIN1; // PC1
  GPIO_InitStruct.Mode = GPIO_MODE_OUTPUT_PP;
  GPIO_InitStruct.Pull = GPIO_NOPULL;
  GPIO_InitStruct.Speed = GPIO_SPEED_FREQ_HIGH;
  HAL_GPIO_Init(TRIG_PORT1, &GPIO_InitStruct);

  GPIO_InitStruct.Pin = ECHO_PIN1; // PA15
  GPIO_InitStruct.Mode = GPIO_MODE_INPUT;
  GPIO_InitStruct.Pull = GPIO_NOPULL;
  HAL_GPIO_Init(ECHO_PORT1, &GPIO_InitStruct);

  /* USER CODE END MX_GPIO_Init_2 */
}

/* USER CODE BEGIN 4 */

/**
  * @brief  TIM6 인터럽트 콜백 - Edge-AI 100Hz 데이터 수집 + IMU 디버깅 (슬라이딩 윈도우)
  */
void HAL_TIM_PeriodElapsedCallback(TIM_HandleTypeDef *htim)
{
    if (htim->Instance == TIM6) {
        // DMA가 사용 중이 아닐 때만 새로운 DMA 전송 시작
        if (!imu_dma_busy) {
            imu_dma_busy = 1;  // DMA 전송 시작 표시

            // DMA로 MPU6050 가속도 데이터 읽기 (비동기, 논블로킹)
            if (MPU6050_ReadAccel_DMA(&hi2c1, imu_dma_buffer) != HAL_OK) {
                // DMA 시작 실패 시 busy 플래그 해제
                imu_dma_busy = 0;
            }
            // 실제 데이터 처리는 HAL_I2C_MemRxCpltCallback에서 수행
        }
    }

    // TIM7 (50Hz) - 오도메트리 업데이트
        if (htim->Instance == TIM7) {
            // [1. Odometry 기능]
            Odom_IMU_Update_IT();
        }
}

/**
  * @brief  I2C Memory Read DMA 완료 콜백 - IMU 데이터 처리
  */
void HAL_I2C_MemRxCpltCallback(I2C_HandleTypeDef *hi2c)
{
    if (hi2c->Instance == I2C1) {
        // DMA로 받은 데이터를 파싱하여 가속도 값 추출
        float ax, ay, az;
        MPU6050_ParseAccelData(imu_dma_buffer, &ax, &ay, &az);

        // Edge-AI 버퍼에 저장 (ax는 1.0g 단위이므로, 16384.0f를 곱함)
        // 순환 버퍼 방식으로 저장 (슬라이딩 윈도우)
        edge_ai_buffer[edge_ai_sample_index * 3 + 0] = ax * 16384.0f;
        edge_ai_buffer[edge_ai_sample_index * 3 + 1] = ay * 16384.0f;
        edge_ai_buffer[edge_ai_sample_index * 3 + 2] = az * 16384.0f;

        // 디버깅용 - 10번마다 한 번씩(0.1초) 센서값 저장
        imu_debug_counter++;
        if (imu_debug_counter >= 10) {
            imu_debug_ax = ax;
            imu_debug_ay = ay;
            imu_debug_az = az;
            imu_debug_ready = 1;  // 출력 준비 완료
            imu_debug_counter = 0;
        }

        edge_ai_sample_index++;
        edge_ai_slide_counter++;

        // 버퍼가 가득 차면 순환 (슬라이딩 윈도우)
        if (edge_ai_sample_index >= EDGE_AI_SAMPLE_COUNT) {
            edge_ai_sample_index = 0;
        }

        // 1초(100개 샘플)마다 AI 판단 트리거
        if (edge_ai_slide_counter >= EDGE_AI_SLIDE_INTERVAL) {
            edge_ai_buffer_ready = 1;
            edge_ai_slide_counter = 0;
        }

        // DMA 전송 완료, busy 플래그 해제
        imu_dma_busy = 0;
        imu_dma_ready = 1;
    }
}

/* USER CODE END 4 */

void Error_Handler(void)
{
  __disable_irq();
  while (1)
  {
  }
}
